# PY32F031xx register map
Vendor: Puya; Series: PY32F0; File version: 1.0.0
CPU: CM0+ r0p1, little endian, no MPU, no FPU, 4 interrupt priority bits
Registers are 32-bit, read-write, reset 0x0 unless marked. A register's access mark holds for its fields unless they carry their own. Offsets are from the block's base; [hi:lo] are bit positions; {n}, {i} and the like mark numbered series; 'fields as' and 'values as' point back to an identical list.

## EXTI — External interrupt/eventcontroller
Base 0x40021800
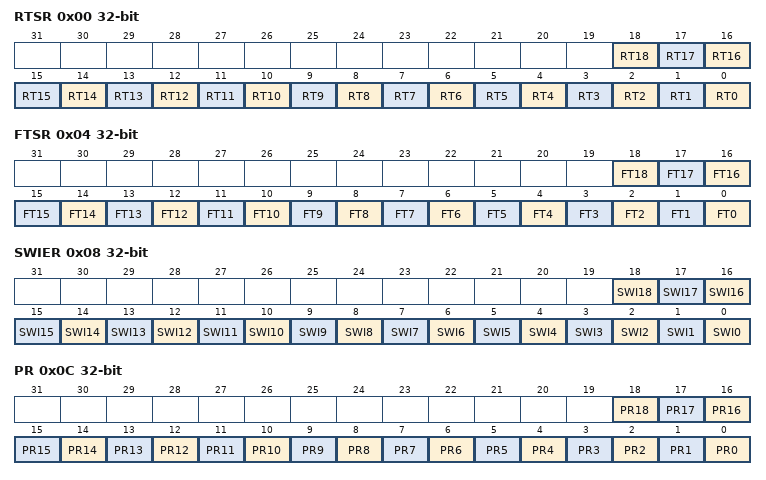
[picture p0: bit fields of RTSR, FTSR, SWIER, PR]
0x00 RTSR — EXTI rising trigger selectionregister
  [n] RT{n} (n=0..18) — Rising trigger event configuration bit of Configurable Event input
0x04 FTSR — EXTI falling trigger selectionregister
  [n] FT{n} (n=0..18) — Falling trigger event configuration bit of Configurable Event input
0x08 SWIER — EXTI software interrupt eventregister
  [n] SWI{n} (n=0..18) — Rising trigger event configuration bit of Configurable Event input
0x0C PR — EXTI pendingregister
  [n] PR{n} (n=14..18) — configurable event inputs x rising edge Pending bit.
  [13] PR13 — configurable event inputs x rising edge Pending bit
  [n] PR{n} (n=0..12) — configurable event inputs x rising edge Pending bit.
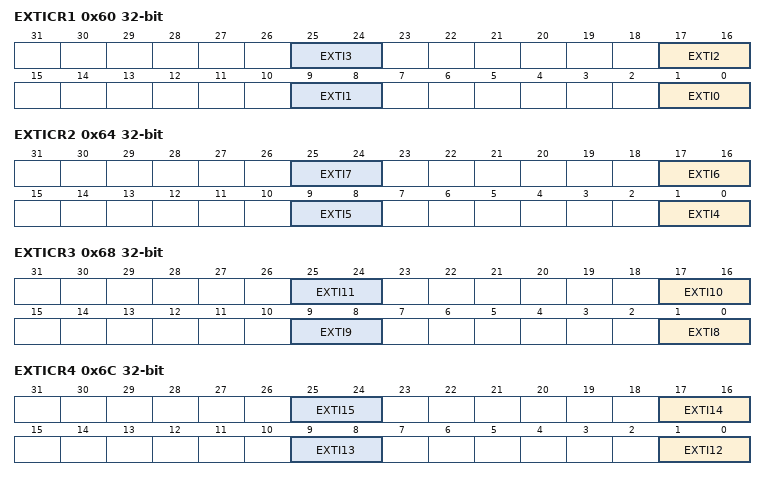
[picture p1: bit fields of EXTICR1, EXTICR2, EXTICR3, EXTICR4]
0x60 EXTICR1 — EXTI external interrupt selectionregister
  [all] fields
    1=0; 2=1
  [8n+1:8n] EXTI{n} (n=0..3) — GPIO port selection
0x64 EXTICR2 — EXTI external interrupt selectionregister
  [all] fields
    1=0; 2=1
  [8n-31:8n-32] EXTI{n} (n=4..7) — GPIO port selection
0x68 EXTICR3 — EXTI external interrupt selectionregister
  [all] fields
    1=0; 2=1
  [8n-63:8n-64] EXTI{n} (n=8..11) — GPIO port selection
0x6C EXTICR4 — EXTI external interrupt selectionregister
  [all] fields
    1=0; 2=1
  [8n-95:8n-96] EXTI{n} (n=12..15) — GPIO port selection
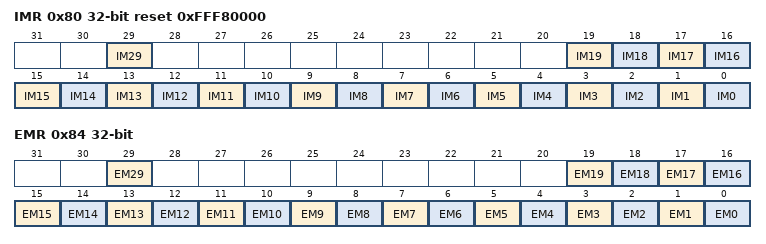
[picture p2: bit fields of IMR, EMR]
0x80 IMR reset 0xFFF80000 — EXTI CPU wakeup with interrupt maskregister
  [29] IM29 — CPU wakeup with interrupt mask on event input
  [n] IM{n} (n=0..19) — CPU wakeup with interrupt mask on event input
0x84 EMR — EXTI CPU wakeup with event maskregister
  [29] EM29 — CPU wakeup with event mask on event input
  [n] EM{n} (n=0..19) — CPU wakeup with event mask on event input

## FLASH
Base 0x40022000
0x00 ACR reset 0x600 — Access control register
  [1:0] LATENCY
    1=0; 2=1
0x08 KEYR wo — Flash key register
  [31:0] KEY — Flash key
0x0C OPTKEYR wo — Option byte key register
  [31:0] OPTKEY — Option byte key
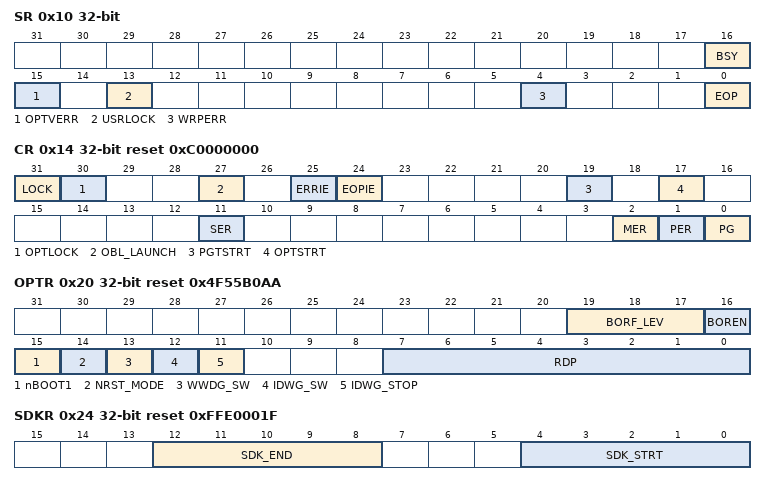
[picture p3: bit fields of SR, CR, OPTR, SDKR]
0x10 SR — Status register
  [16] BSY — Busy
  [15] OPTVERR — Option and Engineering bits loading validity error
  [13] USRLOCK — User data flash lock
  [4] WRPERR — Write protected error
  [0] EOP — End of operation
0x14 CR reset 0xC0000000 — Flash control register
  [31] LOCK — FLASH_CR Lock
  [30] OPTLOCK — Options Lock
  [27] OBL_LAUNCH — Force the option byte loading
  [25] ERRIE — Error interrupt enable
  [24] EOPIE — End of operation interrupt enable
  [19] PGTSTRT — Flash main memory program start
  [17] OPTSTRT — Option byte program start
  [11] SER — Sector erase
  [2] MER — Mass erase
  [1] PER — Page erase
  [0] PG — Programming
0x20 OPTR reset 0x4F55B0AA — Flash option register
  [19:17] BORF_LEV — These bits contain the VDD supply level threshold that activates the reset
  [16] BOREN — BOR reset Level
  [15] nBOOT1 — Boot configuration
  [14] NRST_MODE
  [13] WWDG_SW — Window watchdog selection
  [12] IDWG_SW — Independent watchdog selection
  [11] IDWG_STOP — Stop mode IWDG counter
  [7:0] RDP — Read Protection
    85=LEVEL_1; 170=LEVEL_0
0x24 SDKR reset 0xFFE0001F — Flash SDK address register
  [12:8] SDK_END — SDK area end address
    1=0; 2=1; 4=2; 8=3; 16=4
  [4:0] SDK_STRT — SDK area start address
    1=0; 2=1; 4=2; 8=3; 16=4
0x2C WRPR reset 0xFFFF — Flash WRP addressregister
  [15:0] WRP — WRP address
    1=0; 2=1; 4=2; 8=3; 16=4; 32=5; 64=6; 128=7; 0x100=8; 0x200=9; 0x400=10; 0x800=11; 0x1000=12; 0x2000=13; 0x4000=14; 0x8000=15
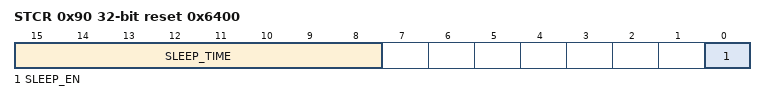
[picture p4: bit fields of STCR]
0x90 STCR reset 0x6400 — Flash sleep time configregister
  [15:8] SLEEP_TIME — FLash sleep time configuration(counter based on HSI_10M)
  [0] SLEEP_EN — FLash sleep enable
0x100 TS0 reset 0xB4 — Flash TS0 register
  [7:0] TS0 — FLash TS0 register
    1=0; 2=1; 4=2; 8=3; 16=4; 32=5; 64=6; 128=7
0x104 TS1 reset 0x1B0 — Flash TS1 register
  [8:0] TS1 — FLash TS1 register
    1=0; 2=1; 4=2; 8=3; 16=4; 32=5; 64=6; 128=7; 0x100=8
0x108 TS2P reset 0xB4 — Flash TS2P register
  [7:0] TS2P — FLash TS2P register
    1=0; 2=1; 4=2; 8=3; 16=4; 32=5; 64=6; 128=7
0x10C TPS3 reset 0x6C0 — Flash TPS3 register
  [10:0] TPS3 — FLash TPS3 register
    1=0; 2=1; 4=2; 8=3; 16=4; 32=5; 64=6; 128=7; 0x100=8; 0x200=9; 0x400=10
0x110 TS3 reset 0xB4 — Flash TS3 register
  [7:0] TS3 — FLash TS3 register
    1=0; 2=1; 4=2; 8=3; 16=4; 32=5; 64=6; 128=7
0x114 PERTPE reset 0xEA60 — Flash PERTPE register
  [16:0] PERTPE — FLash PERTPE register
    1=0; 2=1; 4=2; 8=3; 16=4; 32=5; 64=6; 128=7; 0x100=8; 0x200=9; 0x400=10; 0x800=11; 0x1000=12; 0x2000=13; 0x4000=14; 0x8000=15; 0x10000=16
0x118 SMERTPE reset 0xFD20 — Flash SMERTPE register
  [16:0] SMERTPE — FLash SMERTPE register
    values as PERTPE.PERTPE
0x11C PRGTPE reset 0x8CA0 — Flash PRGTPE register
  [15:0] PRGTPE — FLash PRGTPE register
    values as WRPR.WRP
0x120 PRETPE reset 0x12C0 — Flash PRETPE register
  [12:0] PRETPE — FLash PRETPE register
